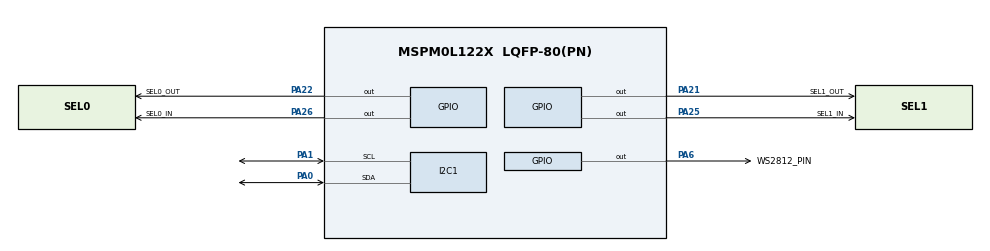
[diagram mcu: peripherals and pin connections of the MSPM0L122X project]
/**
 * @cliArgs --device "MSPM0L122X" --part "Default" --package "LQFP-80(PN)" --product "mspm0_sdk@2.05.01.01"
 * @versions {"tool":"1.24.0+4110"}
 */

/**
 * Import the modules used in this configuration.
 */
const Board         = scripting.addModule("/ti/driverlib/Board");
const GPIO          = scripting.addModule("/ti/driverlib/GPIO", {}, false);
const GPIO1         = GPIO.addInstance();
const GPIO2         = GPIO.addInstance();
const I2C           = scripting.addModule("/ti/driverlib/I2C", {}, false);
const I2C1          = I2C.addInstance();
const SYSCTL        = scripting.addModule("/ti/driverlib/SYSCTL");
const ProjectConfig = scripting.addModule("/ti/project_config/ProjectConfig");

/**
 * Write custom configuration values to the imported modules.
 */
Board.configureUnused = true;

GPIO1.$name                          = "GPIO_GRP_0";
GPIO1.associatedPins.create(4);
GPIO1.associatedPins[0].$name        = "SEL0_IN";
GPIO1.associatedPins[0].assignedPort = "PORTA";
GPIO1.associatedPins[0].initialValue = "SET";
GPIO1.associatedPins[0].pin.$assign  = "PA26";
GPIO1.associatedPins[1].$name        = "SEL1_IN";
GPIO1.associatedPins[1].assignedPort = "PORTA";
GPIO1.associatedPins[1].initialValue = "SET";
GPIO1.associatedPins[1].pin.$assign  = "PA25";
GPIO1.associatedPins[2].$name        = "SEL0_OUT";
GPIO1.associatedPins[2].assignedPort = "PORTA";
GPIO1.associatedPins[2].initialValue = "SET";
GPIO1.associatedPins[2].pin.$assign  = "PA22";
GPIO1.associatedPins[3].$name        = "SEL1_OUT";
GPIO1.associatedPins[3].assignedPort = "PORTA";
GPIO1.associatedPins[3].initialValue = "SET";
GPIO1.associatedPins[3].pin.$assign  = "PA21";

GPIO2.$name                          = "GPIO_GRP_1";
GPIO2.associatedPins[0].$name        = "WS2812_PIN";
GPIO2.associatedPins[0].assignedPort = "PORTA";
GPIO2.associatedPins[0].pin.$assign  = "PA6";

I2C1.$name                     = "I2C_0";
I2C1.basicEnableTarget         = true;
I2C1.advDigitalGlitchFilter    = "CLOCKS_1";
I2C1.basicTargetAddress        = 0x5D;
I2C1.peripheral.sdaPin.$assign = "PA0";
I2C1.peripheral.sclPin.$assign = "PA1";
I2C1.sdaPinConfig.$name        = "ti_driverlib_gpio_GPIOPinGeneric0";
I2C1.sclPinConfig.$name        = "ti_driverlib_gpio_GPIOPinGeneric1";


ProjectConfig.deviceSpin = "MSPM0L1227";

/**
 * Pinmux solution for unlocked pins/peripherals. This ensures that minor changes to the automatic solver in a future
 * version of the tool will not impact the pinmux you originally saw.  These lines can be completely deleted in order to
 * re-solve from scratch.
 */
Board.peripheral.$suggestSolution          = "DEBUGSS";
Board.peripheral.swclkPin.$suggestSolution = "PA20";
Board.peripheral.swdioPin.$suggestSolution = "PA19";
I2C1.peripheral.$suggestSolution           = "I2C0";
SYSCTL.peripheral.$suggestSolution         = "SYSCTL";
